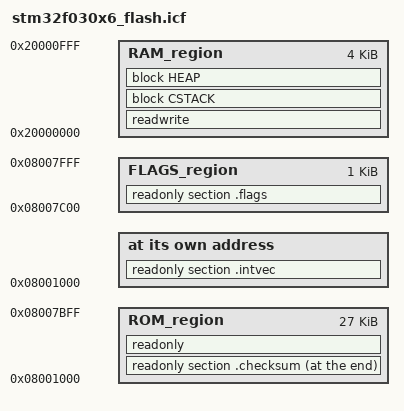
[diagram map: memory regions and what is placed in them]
/*###ICF### Section handled by ICF editor, don't touch! ****/
/*-Editor annotation file-*/
/* IcfEditorFile="$TOOLKIT_DIR$\config\ide\IcfEditor\cortex_v1_0.xml" */

/*-Boot/App split-*/
define symbol BOOT_start__ = 0x08000000;
define symbol BOOT_end__   = 0x08000FFF;   /* 4 KB bootloader */

define symbol APP_start__  = 0x08001000;   /* приложение после boot */
define symbol APP_end__    = 0x08007BFF;   /* до страницы флагов */


/*-Specials-*/
define symbol __ICFEDIT_intvec_start__ = APP_start__;
/*-Memory Regions-*/
define symbol __ICFEDIT_region_ROM_start__ = APP_start__;
define symbol __ICFEDIT_region_ROM_end__   = APP_end__;
define symbol __ICFEDIT_region_RAM_start__ = 0x20000000;
define symbol __ICFEDIT_region_RAM_end__   = 0x20000FFF;


/* Последняя страница 1 КБ под флаги */
define symbol FLAGS_start__ = 0x08007C00;
define symbol FLAGS_end__   = 0x08007FFF;
/*-Sizes-*/
define symbol __ICFEDIT_size_cstack__ = 0x400;
define symbol __ICFEDIT_size_heap__   = 0x400;
/**** End of ICF editor section. ###ICF###*/

define memory mem with size = 4G;
define region ROM_region   = mem:[from __ICFEDIT_region_ROM_start__   to __ICFEDIT_region_ROM_end__];
define region FLAGS_region = mem:[from FLAGS_start__ to FLAGS_end__];
define region RAM_region   = mem:[from __ICFEDIT_region_RAM_start__   to __ICFEDIT_region_RAM_end__];

define block CSTACK    with alignment = 8, size = __ICFEDIT_size_cstack__   { };
define block HEAP      with alignment = 8, size = __ICFEDIT_size_heap__     { };

initialize by copy { readwrite };
do not initialize  { section .noinit };

place at address mem:__ICFEDIT_intvec_start__ { readonly section .intvec };

/* контрольная сумма crc32 */
place at end of ROM_region { readonly section .checksum };

place in FLAGS_region { readonly section .flags };
place in ROM_region   { readonly };
place in RAM_region   { readwrite,
                        block CSTACK, block HEAP };

export symbol __ICFEDIT_region_RAM_start__;
export symbol __ICFEDIT_region_RAM_end__;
